AUTOSAR XML (schema 4-0-3)
package /ComponentTypes
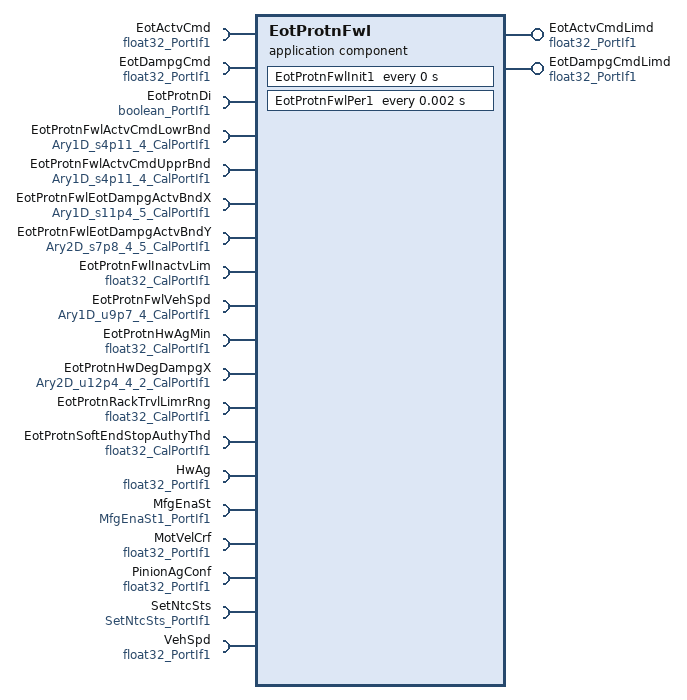
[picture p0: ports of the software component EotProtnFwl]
  application sw component type EotProtnFwl
    provide port EotActvCmdLimd: nonqueued-sender-com-spec{data-element=Val, init-value=0}, provided-interface=float32_PortIf1
    provide port EotDampgCmdLimd: nonqueued-sender-com-spec{data-element=Val, init-value=0}, provided-interface=float32_PortIf1
    19 x require port:
      EotActvCmd: nonqueued-receiver-com-spec{data-element=Val, filter=data-filter-type=ALWAYS, init-value=0}, required-interface=float32_PortIf1
      EotDampgCmd: nonqueued-receiver-com-spec{data-element=Val, filter=data-filter-type=ALWAYS, init-value=0}, required-interface=float32_PortIf1
      EotProtnDi: nonqueued-receiver-com-spec{data-element=Logl, filter=data-filter-type=ALWAYS, init-value=0}, required-interface=boolean_PortIf1
      EotProtnFwlActvCmdLowrBnd: parameter-require-com-spec{init-value=[-512, -512, -512, -512], parameter=Ary1D}, required-interface=Ary1D_s4p11_4_CalPortIf1
      EotProtnFwlActvCmdUpprBnd: parameter-require-com-spec{init-value=[18022, 18022, 18022, 18022], parameter=Ary1D}, required-interface=Ary1D_s4p11_4_CalPortIf1
      EotProtnFwlEotDampgActvBndX: parameter-require-com-spec{init-value=[-11200, -80, 160, 800, 11200], parameter=Ary1D}, required-interface=Ary1D_s11p4_5_CalPortIf1
      EotProtnFwlEotDampgActvBndY: parameter-require-com-spec{init-value=[5 x 2253, 5 x 2253, 5 x 2253, 5 x 2253], parameter=Ary2D}, required-interface=Ary2D_s7p8_4_5_CalPortIf1
      EotProtnFwlInactvLim: parameter-require-com-spec{init-value=0.1, parameter=Val}, required-interface=float32_CalPortIf1
      EotProtnFwlVehSpd: parameter-require-com-spec{init-value=[0, 2560, 5120, 7680], parameter=Ary1D}, required-interface=Ary1D_u9p7_4_CalPortIf1
      EotProtnHwAgMin: parameter-require-com-spec{init-value=550, parameter=Val}, required-interface=float32_CalPortIf1
      EotProtnHwDegDampgX: parameter-require-com-spec{init-value=[[1920, 0], [1920, 0], [1920, 0], [1920, 0]], parameter=Ary2D}, required-interface=Ary2D_u12p4_4_2_CalPortIf1
      EotProtnRackTrvlLimrRng: parameter-require-com-spec{init-value=20, parameter=Val}, required-interface=float32_CalPortIf1
      EotProtnSoftEndStopAuthyThd: parameter-require-com-spec{init-value=0.9, parameter=Val}, required-interface=float32_CalPortIf1
      HwAg: nonqueued-receiver-com-spec{data-element=Val, filter=data-filter-type=ALWAYS, init-value=0}, required-interface=float32_PortIf1
      MfgEnaSt: nonqueued-receiver-com-spec{data-element=Val, filter=data-filter-type=ALWAYS, init-value=0}, required-interface=MfgEnaSt1_PortIf1
      MotVelCrf: nonqueued-receiver-com-spec{data-element=Val, filter=data-filter-type=ALWAYS, init-value=0}, required-interface=float32_PortIf1
      PinionAgConf: nonqueued-receiver-com-spec{data-element=Val, filter=data-filter-type=ALWAYS, init-value=0}, required-interface=float32_PortIf1
      SetNtcSts: client-com-spec=Oper, required-interface=SetNtcSts_PortIf1
      VehSpd: nonqueued-receiver-com-spec{data-element=Val, filter=data-filter-type=ALWAYS, init-value=0}, required-interface=float32_PortIf1
    behavior EotProtnFwl_InternalBehavior
      ar-typed-per-instance-memorys:
        12 x data, all with sw-calibration-access=READ-ONLY:
          dEotProtnFwlEotActvCmdActvLowrBnd: type=float32
          dEotProtnFwlEotActvCmdActvUpprBnd: type=float32
          dEotProtnFwlEotActvCmdMod: type=uint8
          dEotProtnFwlEotActvCmdOverActvLim: type=boolean
          dEotProtnFwlEotActvCmdOverInactvLim: type=boolean
          dEotProtnFwlEotDampgActvLowrBnd: type=float32
          dEotProtnFwlEotDampgActvUpprBnd: type=float32
          dEotProtnFwlEotDampgFwX0: type=float32
          dEotProtnFwlEotDampgMod: type=uint8
          dEotProtnFwlEotDampgOverActvLim: type=boolean
          dEotProtnFwlEotDampgOverInactvLim: type=boolean
          dEotProtnFwlPinionAgConfSts: type=boolean
      timing event EotProtnFwl_InitEvent: start-on-event=EotProtnFwlInit1, period=0
      timing event TMT_EotProtnFwlPer1: start-on-event=EotProtnFwlPer1, period=0.002
      runnable EotProtnFwlInit1
        sync call SC_SetNtcSts_Oper: operation=SetNtcSts.Oper, timeout=0
      runnable EotProtnFwlPer1
        data-receive-point-by-arguments:
          8 x access:
            REC_EotActvCmd_Val: accessed-variable=EotActvCmd.Val
            REC_EotDampgCmd_Val: accessed-variable=EotDampgCmd.Val
            REC_EotProtnDi_Logl: accessed-variable=EotProtnDi.Logl
            REC_HwAg_Val: accessed-variable=HwAg.Val
            REC_MfgEnaSt_Val: accessed-variable=MfgEnaSt.Val
            REC_MotVelCrf_Val: accessed-variable=MotVelCrf.Val
            REC_PinionAgConf_Val: accessed-variable=PinionAgConf.Val
            REC_VehSpd_Val: accessed-variable=VehSpd.Val
        data-send-points:
          access SEND_EotActvCmdLimd_Val: accessed-variable=EotActvCmdLimd.Val
          access SEND_EotDampgCmdLimd_Val: accessed-variable=EotDampgCmdLimd.Val
        sync call SC_SetNtcSts_Oper: operation=SetNtcSts.Oper, timeout=0
  swc implementation EotProtnFwl_Implementation: behavior=EotProtnFwl_InternalBehavior
    code-descriptors:
      code Default: artifact-descriptors=autosar-engineering-object={short-label=Default, category=SWSRC}
